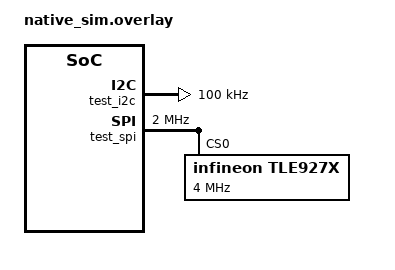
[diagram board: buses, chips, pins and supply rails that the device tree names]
/*
 * Copyright (c) 2023 Nordic Semiconductor ASA
 * SPDX-License-Identifier: Apache-2.0
 */

#include <zephyr/dt-bindings/regulator/tle927x.h>

/ {
	test {
		#address-cells = <1>;
		#size-cells = <1>;

		test_i2c: i2c@11112222 {
			compatible = "vnd,i2c";
			reg = <0x11112222 0x1000>;
			#address-cells = <1>;
			#size-cells = <0>;
			clock-frequency = <100000>;
			status = "okay";

#include "native_sim_i2c.dtsi"
		};

		test_gpio: gpio@deadbeef {
			compatible = "vnd,gpio";
			reg = <0xdeadbeef 0x1000>;
			gpio-controller;
			#gpio-cells = <0x2>;
			status = "okay";
		};

		test_spi: spi@33334444 {
			#address-cells = <1>;
			#size-cells = <0>;
			compatible = "vnd,spi";
			reg = <0x33334444 0x1000>;
			status = "okay";
			clock-frequency = <2000000>;

			tle927x@0 {
				compatible = "infineon,tle927x";
				reg = <0>;
				spi-max-frequency = <4000000>;
				status = "okay";

				vcc2 {
					compatible = "infineon,tle927x-vcc2";
					regulator-initial-mode = <TLE927X_VCC2_MODE_NORMAL_STOP>;
				};
			};
		};

#include "native_sim_misc.dtsi"
	};
};
